# MINI58DE_v1 register map
File version: 1.0
Registers are 32-bit, read-write, reset 0x0 unless marked. A register's access mark holds for its fields unless they carry their own. Offsets are from the block's base; [hi:lo] are bit positions; {n}, {i} and the like mark numbered series; 'fields as' and 'values as' point back to an identical list.

## ADC — ADC Register Map
Base 0x400E0000
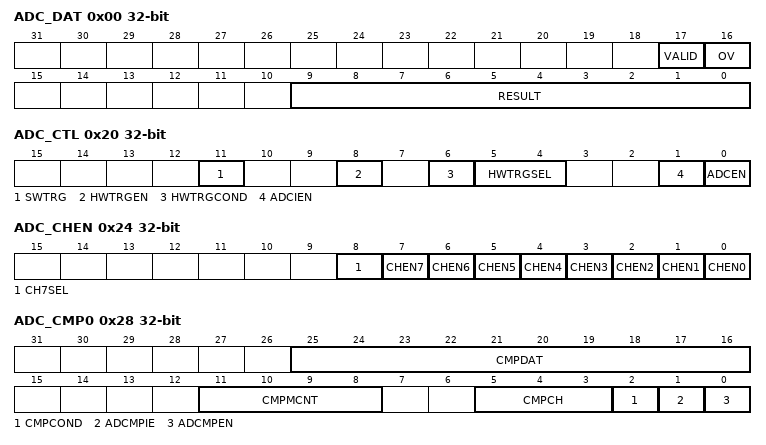
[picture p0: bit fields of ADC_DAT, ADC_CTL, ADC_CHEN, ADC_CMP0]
0x00 ADC_DAT ro — A/D Data Register
  [17] VALID — Valid Flag. This bit is set to 1 when ADC conversion is completed and cleared by hardware after the ADC_DAT register is read.
    0=Data in RESULT[9:0] bits not valid; 1=Data in RESULT[9:0] bits valid
  [16] OV — Over Run Flag. If converted data in RESULT[9:0] has not been read before the new conversion result is loaded to this register, OV is set to 1. It is cleared by hardware after the ADC_DAT register is read.
    0=Data in RESULT[9:0] is recent conversion result; 1=Data in RESULT[9:0] overwrote
  [9:0] RESULT — A/D Conversion Result. This field contains conversion result of ADC.
0x20 ADC_CTL — A/D Control Register
  [11] SWTRG — Software Trigger A/D Conversion Start. SWTRG bit can be set to 1 from two sources: software and external pin STADC. SWTRG will be cleared to 0 by hardware automatically after conversion complete.
    0=Conversion stopped and A/D converter entered idle state; 1=Conversion start
  [8] HWTRGEN — Hardware External Trigger Enable Bit. Enable or disable triggering of A/D conversion by external STADC pin. If external trigger is enabled, the SWTRG bit can be set to 1 by the selected hardware trigger source.
    0=External trigger Disabled; 1=External trigger Enabled
  [6] HWTRGCOND — Hardware External Trigger Condition. This bit decides whether the external pin STADC trigger event is falling or raising edge. The signal must be kept at stable state at least 4 PCLKs at high and low state for edge trigger.
    0=Falling edge; 1=Raising edge
  [5:4] HWTRGSEL — Hardware Trigger Source Select Bit. Note: Software should disable TRGEN and SWTRG before change TRGS.
    0=A/D conversion is started by external STADC pin; 3=A/D conversion is started by PWM trigger
  [1] ADCIEN — A/D Interrupt Enable Bit. A/D conversion end interrupt request is generated if ADCIEN bit is set to 1.
    0=A/D interrupt function Disabled; 1=A/D interrupt function Enabled
  [0] ADCEN — A/D Converter Enable Bit. Note: Before starting A/D conversion function, this bit should be set to 1. Clear it to 0 to disable A/D converter analog circuit to save power consumption.
    0=A/D Converter Disabled; 1=A/D Converter Enabled
0x24 ADC_CHEN — A/D Channel Enable Register
  [8] CH7SEL — Analog Input Channel 7 Selection. Note: When software selects the band-gap voltage as the analog input source of ADC channel 7, the ADC clock rate needs to be limited to lower than 300 kHz.
    0=External analog input; 1=Internal band-gap voltage (VBG)
  [n] CHEN{n} (n=1..7) — Analog Input Channel {n} Enable Bit
    0=Channel {n} Disabled; 1=Channel {n} Enabled
  [0] CHEN0 — Analog Input Channel 0 Enable Bit. Note: If software enables more than one channel, the channel with the smallest number will be selected and the other enabled channels will be ignored.
    0=Channel 0 Disabled; 1=Channel 0 Enabled
0x28 ADC_CMP0 — A/D Compare Register 0
  [25:16] CMPDAT — Comparison Data. The 10-bit data is used to compare with conversion result of specified channel.
  [11:8] CMPMCNT — Compare Match Count. When the specified A/D channel analog conversion result matches the compare condition defined by CMPCOND[2], the internal match counter will increase 1. When the internal counter reaches the value to (CMPMCNT+1), the ADCMPFx bit will be set.
  [5:3] CMPCH — Compare Channel Selection. Set this field to select which channel's result to be compared. Note: Valid setting of this field is channel 0~7.
  [2] CMPCOND — Compare Condition. Note: When the internal counter reaches the value to (CMPMCNT+1), the ADCMPFx bit will be set.
    0=Set the compare condition as that when a 10-bit A/D conversion result is less than the 10-bit CMPDAT (ADC_CMPx[25:16]), the internal match counter will increase one; 1=Set the compare condition as that when a 10-bit A/D conversion result is greater or equal to the 10-bit CMPDAT (ADC_CMPx[25:16]), the internal match counter will increase one
  [1] ADCMPIE — A/D Compare Interrupt Enable Bit. If the compare function is enabled and the compare condition matches the setting of CMPCOND and CMPMCNT, ADCMPIE bit will be asserted, in the meanwhile, if ADCMPIE is set to 1, a compare interrupt request is generated.
    0=Compare function interrupt Disabled; 1=Compare function interrupt Enabled
  [0] ADCMPEN — A/D Compare Enable Bit. Set 1 to this bit to enable comparing CMPDAT (ADC_CMPx[25:16]) with specified channel conversion results when converted data is loaded into the ADC_DAT register.
    0=Compare function Disabled; 1=Compare function Enabled
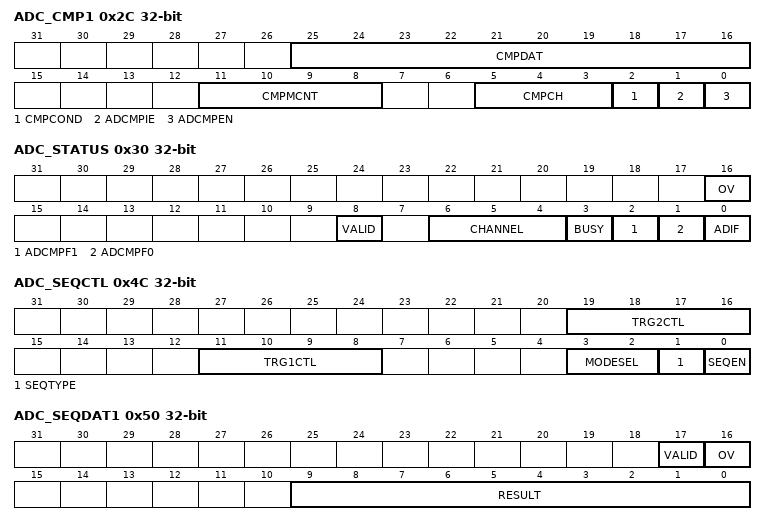
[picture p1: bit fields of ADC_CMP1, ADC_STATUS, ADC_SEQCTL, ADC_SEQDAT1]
0x2C ADC_CMP1 — A/D Compare Register 1
  fields as ADC_CMP0
0x30 ADC_STATUS — A/D Status Register
  [16] OV ro — Overrun Flag (Read Only). It is a mirror to OV bit in ADC_DAT register.
  [8] VALID ro — Data Valid Flag (Read Only). It is a mirror of VALID bit in ADC_DAT register.
  [6:4] CHANNEL ro — Current Conversion Channel (Read Only)
  [3] BUSY ro — BUSY/IDLE (Read Only). This bit is mirror of as SWTRG bit in ADC_CTL
    0=A/D converter is in idle state; 1=A/D converter is busy at conversion
  [2] ADCMPF1 — A/D Compare Flag 1. When the selected channel A/D conversion result meets the setting condition in ADC_CMP1, this bit is set to 1. Note: This bit can be cleared to 0 by software writing 1.
    0=Conversion result in ADC_DAT does not meet the ADC_CMP1 setting; 1=Conversion result in ADC_DAT meets the ADC_CMP1 setting
  [1] ADCMPF0 — A/D Compare Flag 0. When the selected channel A/D conversion result meets the setting condition in ADC_CMP0, this bit is set to 1. Note: This bit can be cleared to 0 by software writing 1.
    0=Conversion result in ADC_DAT does not meet the ADC_CMP0 setting; 1=Conversion result in ADC_DAT meets the ADC_CMP0 setting
  [0] ADIF — A/D Conversion End Flag. A status flag that indicates the end of A/D conversion. ADIF is set to 1 When A/D conversion ends. Note: This bit can be cleared to 0 by software writing 1.
0x44 ADC_TRGDLY — A/D Trigger Delay Control Register
  [7:0] DELAY — PWM Trigger Delay Timer. Set this field will delay ADC start conversion time after PWM trigger. PWM trigger delay time is (4 * DELAY) * system clock.
0x48 ADC_EXTSMPT — A/D Sampling Time Counter Register
  [3:0] EXTSMPT — Additional ADC Sample Clock. If the ADC input is unstable, user can set this register to increase the sampling time to get a stable ADC input signal. The default sampling time is 1 ADC clocks. The additional clock number will be inserted to lengthen the sampling clock.
    0=Number of additional clock cycles is 0; 1=Number of additional clock cycles is 1; 2=Number of additional clock cycles is 2; 3=Number of additional clock cycles is 4; 4=Number of additional clock cycles is 8; 5=Number of additional clock cycles is 16; 6=Number of additional clock cycles is 32; 7=Number of additional clock cycles is 64; 8=Number of additional clock cycles is 128; 9=Number of additional clock cycles is 256; 10=Number of additional clock cycles is 512; {v}=Number of additional clock cycles is 1024 (v=11..15)
0x4C ADC_SEQCTL — A/D PWM Sequential Mode Control Register
  [19:16] TRG2CTL — PWM Trigger Source Selection For TRG2CTL[3:2]. Note: PWM trigger source is valid for 1-shunt type.
    0=PWM Trigger source is PWM0. Rising of the selected PWM; 1=PWM Trigger source is PWM2. Center of the selected PWM; 2=PWM Trigger source is PWM4. Falling of the selected PWM; 3=PWM Trigger source is reserved. Period of the selected PWM
  [11:8] TRG1CTL — PWM Trigger Source Selection For TRG1CTL[3:2]. Note: PWM trigger source is valid for 1-shunt and 2/3-shunt type.
    values as TRG2CTL
  [3:2] MODESEL — ADC Sequential Mode Selection
    0=Issue ADC_INT after Channel 0 then Channel 1 conversion finishes when SEQEN =1; 1=Issue ADC_INT after Channel 1 then Channel 2 conversion finishes when SEQEN =1; 2=Issue ADC_INT after Channel 0 then Channel 2 conversion finishes when SEQEN =1
  [1] SEQTYPE — ADC Sequential Mode Type
    0=ADC delay time is only inserted before the first conversion. The second conversion starts immediately after the first conversion is completed. (for 2/3-shunt type); 1=ADC delay time is inserted before each conversion. (for 1-shunt type)
  [0] SEQEN — ADC Sequential Mode Enable Bit. When ADC sequential mode is enabled, two of three ADC channels from 0 to 2 will automatically convert analog data in the sequence of channel [0, 1] or channel[1, 2] or channel[0, 2] defined by MODESEL (ADC_SEQCTL[3:2]).
    0=ADC sequential mode Disabled; 1=ADC sequential mode Enabled
0x50 ADC_SEQDAT1 ro — A/D PWM Sequential Mode First Result Register1
  [17] VALID — Valid Flag. This bit is set to 1 when ADC conversion is completed and cleared by hardware after the ADC_DAT register is read.
    values as ADC_DAT.VALID
  [16] OV — Over Run Flag. If converted data in RESULT[9:0] has not been read before the new conversion result is loaded to this register, OV is set to 1. It is cleared by hardware after the ADC_DAT register is read.
    0=Data in RESULT[9:0] is recent conversion result; 1=Data in RESULT[9:0] overwritten
  [9:0] RESULT — A/D PWM Sequential Mode Conversion Result. This field contains conversion result of ADC.
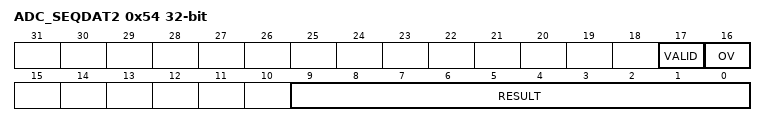
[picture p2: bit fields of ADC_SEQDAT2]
0x54 ADC_SEQDAT2 ro — A/D PWM Sequential Mode Second Result Register1
  fields as ADC_SEQDAT1
